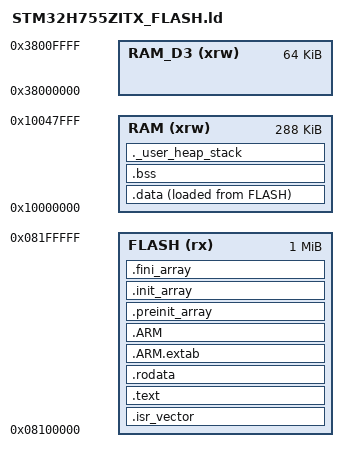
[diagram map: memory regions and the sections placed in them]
/*
******************************************************************************
**
**  File        : LinkerScript.ld
**
**  Author      : STM32CubeIDE
**
**  Abstract    : Linker script for STM32H7 series
**                1024Kbytes FLASH and 288Kbytes RAM
**
**                Set heap size, stack size and stack location according
**                to application requirements.
**
**                Set memory bank area and size if external memory is used.
**
**  Target      : STMicroelectronics STM32
**
**  Distribution: The file is distributed as is, without any warranty
**                of any kind.
**
*****************************************************************************
** @attention
**
** Copyright (c) 2026 STMicroelectronics.
** All rights reserved.
**
** This software is licensed under terms that can be found in the LICENSE file
** in the root directory of this software component.
** If no LICENSE file comes with this software, it is provided AS-IS.
**
****************************************************************************
*/

/* Entry Point */
ENTRY(Reset_Handler)

/* Highest address of the user mode stack */
_estack = ORIGIN(RAM) + LENGTH(RAM);

/* PERMANENT FIX: stack/heap increased for AI + MPU + IPC */
_Min_Heap_Size  = 0x1000 ; /* 4 KB heap  */
_Min_Stack_Size = 0x4000 ; /* 16 KB stack */

/* Specify the memory areas */
MEMORY
{
  FLASH  (rx)   : ORIGIN = 0x08100000, LENGTH = 1024K
  RAM    (xrw)  : ORIGIN = 0x10000000, LENGTH = 288K
  RAM_D3 (xrw)  : ORIGIN = 0x38000000, LENGTH = 64K
}

/* Define output sections */
SECTIONS
{
  /* The startup code goes first into FLASH */
  .isr_vector :
  {
    . = ALIGN(4);
    KEEP(*(.isr_vector))
    . = ALIGN(4);
  } >FLASH

  /* The program code and other data goes into FLASH */
  .text :
  {
    . = ALIGN(4);
    *(.text)
    *(.text*)
    *(.glue_7)
    *(.glue_7t)
    *(.eh_frame)

    KEEP (*(.init))
    KEEP (*(.fini))

    . = ALIGN(4);
    _etext = .;
  } >FLASH

  /* Constant data goes into FLASH */
  .rodata :
  {
    . = ALIGN(4);
    *(.rodata)
    *(.rodata*)
    . = ALIGN(4);
  } >FLASH

  .ARM.extab (READONLY) :
  {
    *(.ARM.extab* .gnu.linkonce.armextab.*)
  } >FLASH

  .ARM (READONLY) :
  {
    __exidx_start = .;
    *(.ARM.exidx*)
    __exidx_end = .;
  } >FLASH

  .preinit_array (READONLY) :
  {
    PROVIDE_HIDDEN (__preinit_array_start = .);
    KEEP (*(.preinit_array*))
    PROVIDE_HIDDEN (__preinit_array_end = .);
  } >FLASH

  .init_array (READONLY) :
  {
    PROVIDE_HIDDEN (__init_array_start = .);
    KEEP (*(SORT(.init_array.*)))
    KEEP (*(.init_array*))
    PROVIDE_HIDDEN (__init_array_end = .);
  } >FLASH

  .fini_array (READONLY) :
  {
    PROVIDE_HIDDEN (__fini_array_start = .);
    KEEP (*(SORT(.fini_array.*)))
    KEEP (*(.fini_array*))
    PROVIDE_HIDDEN (__fini_array_end = .);
  } >FLASH

  /* used by the startup to initialize data */
  _sidata = LOADADDR(.data);

  /* Initialized data sections goes into RAM, load LMA copy after code */
  .data :
  {
    . = ALIGN(4);
    _sdata = .;
    *(.data)
    *(.data*)
    *(.RamFunc)
    *(.RamFunc*)

    . = ALIGN(4);
    _edata = .;
  } >RAM AT> FLASH

  /* Uninitialized data section */
  . = ALIGN(4);
  .bss :
  {
    _sbss = .;
    __bss_start__ = _sbss;
    *(.bss)
    *(.bss*)
    *(COMMON)

    . = ALIGN(4);
    _ebss = .;
    __bss_end__ = _ebss;
  } >RAM

  /* User_heap_stack section, used to check that there is enough RAM left */
  ._user_heap_stack :
  {
    . = ALIGN(8);
    PROVIDE ( end = . );
    PROVIDE ( _end = . );
    . = . + _Min_Heap_Size;
    . = . + _Min_Stack_Size;
    . = ALIGN(8);
  } >RAM

  /* Remove information from the standard libraries */
  /DISCARD/ :
  {
    libc.a ( * )
    libm.a ( * )
    libgcc.a ( * )
  }

  .ARM.attributes 0 : { *(.ARM.attributes) }
}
